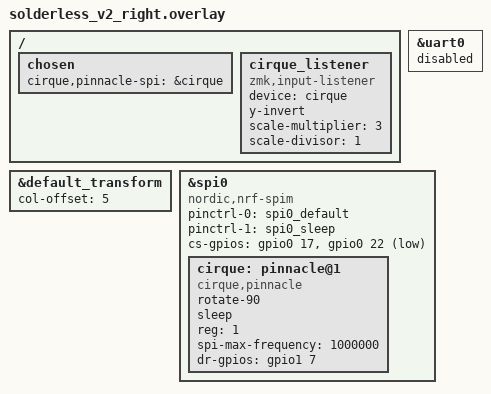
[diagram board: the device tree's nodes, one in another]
/*
 * Copyright (c) 2020 The ZMK Contributors
 *
 * SPDX-License-Identifier: MIT
 */

#include "solderless_v2.dtsi"

/ {
	chosen {
        cirque,pinnacle-spi = &cirque;
	};
};

&default_transform {
	col-offset = <5>;
};

&uart0 {
    status = "disabled";
};

nice_view_spi: &spi0 {
    compatible = "nordic,nrf-spim";
    status = "okay";
    
    pinctrl-0 = <&spi0_default>;
    pinctrl-1 = <&spi0_sleep>;
    pinctrl-names = "default", "sleep";

	cs-gpios = <&gpio0 17 GPIO_ACTIVE_HIGH>, <&gpio0 22 GPIO_ACTIVE_LOW>;

    cirque: pinnacle@1 {
        compatible = "cirque,pinnacle";
		status = "okay";
        rotate-90;
        sleep;
        reg = <1>;
        spi-max-frequency = <1000000>;
        dr-gpios = <&gpio1 7 GPIO_ACTIVE_HIGH>;
    };
};

/ {
    cirque_listener {
      compatible = "zmk,input-listener";
      device = <&cirque>;
      y-invert;
      scale-multiplier = <3>;
      scale-divisor = <1>;
    };
  };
